# STM32F30xxx register map
File version: 1.0
Registers are 32-bit, read-write, reset 0x0 unless marked. A register's access mark holds for its fields unless they carry their own. Offsets are from the block's base; [hi:lo] are bit positions; {n}, {i} and the like mark numbered series; 'fields as' and 'values as' point back to an identical list.

## DMA1 — DMA controller 1
Base 0x40020000
Same registers: DMA2 0x40020400
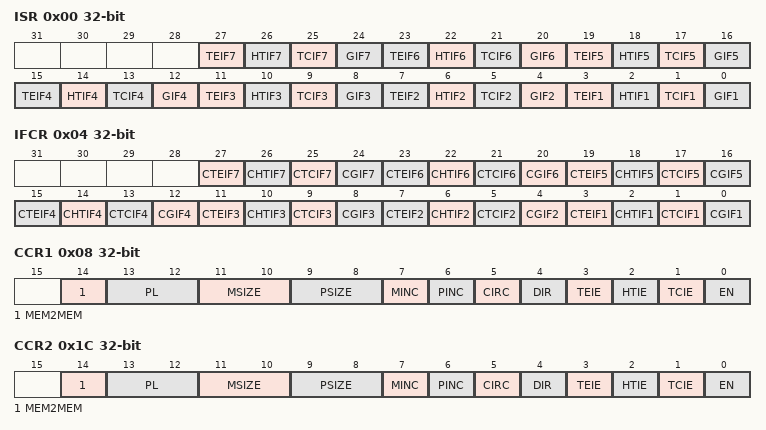
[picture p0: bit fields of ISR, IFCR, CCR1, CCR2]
0x00 ISR ro — DMA interrupt status register (DMA_ISR)
  [4n-1] TEIF{n} (n=1..7) — Channel {n} Transfer Error flag
  [4n-2] HTIF{n} (n=1..7) — Channel {n} Half Transfer Complete flag
  [4n-3] TCIF{n} (n=1..7) — Channel {n} Transfer Complete flag
  [4n-4] GIF{n} (n=1..7) — Channel {n} Global interrupt flag
0x04 IFCR wo — DMA interrupt flag clear register (DMA_IFCR)
  [4n-1] CTEIF{n} (n=1..7) — Channel {n} Transfer Error clear
  [4n-2] CHTIF{n} (n=1..7) — Channel {n} Half Transfer clear
  [4n-3] CTCIF{n} (n=1..7) — Channel {n} Transfer Complete clear
  [4n-4] CGIF{n} (n=1..7) — Channel {n} Global interrupt clear
0x08 CCR1 — DMA channel configuration register (DMA_CCR)
  [14] MEM2MEM — Memory to memory mode
  [13:12] PL — Channel Priority level
  [11:10] MSIZE — Memory size
  [9:8] PSIZE — Peripheral size
  [7] MINC — Memory increment mode
  [6] PINC — Peripheral increment mode
  [5] CIRC — Circular mode
  [4] DIR — Data transfer direction
  [3] TEIE — Transfer error interrupt enable
  [2] HTIE — Half Transfer interrupt enable
  [1] TCIE — Transfer complete interrupt enable
  [0] EN — Channel enable
0x0C CNDTR1 — DMA channel 1 number of data register
  [15:0] NDT — Number of data to transfer
0x10 CPAR1 — DMA channel 1 peripheral address register
  [31:0] PA — Peripheral address
{0x0+0x14*i} CMAR{i} (i=1..7) — DMA channel {i} memory address register
  [31:0] MA — Memory address
0x1C CCR2 — DMA channel configuration register (DMA_CCR)
  fields as CCR1
0x20 CNDTR2 — DMA channel 2 number of data register
  [15:0] NDT — Number of data to transfer
0x24 CPAR2 — DMA channel 2 peripheral address register
  [31:0] PA — Peripheral address
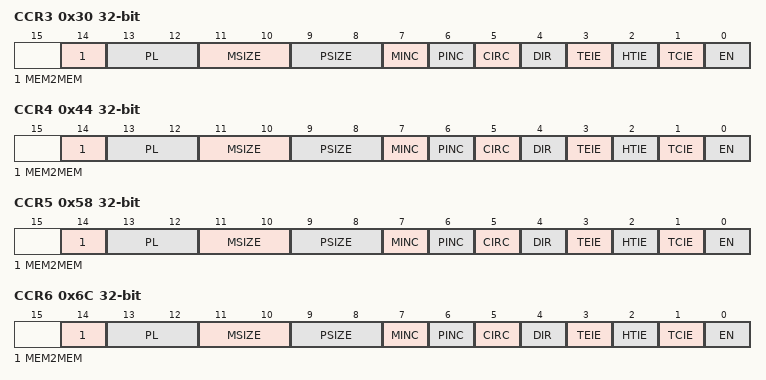
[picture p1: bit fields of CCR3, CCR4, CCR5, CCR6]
0x30 CCR3 — DMA channel configuration register (DMA_CCR)
  fields as CCR1
0x34 CNDTR3 — DMA channel 3 number of data register
  [15:0] NDT — Number of data to transfer
0x38 CPAR3 — DMA channel 3 peripheral address register
  [31:0] PA — Peripheral address
0x44 CCR4 — DMA channel configuration register (DMA_CCR)
  fields as CCR1
0x48 CNDTR4 — DMA channel 4 number of data register
  [15:0] NDT — Number of data to transfer
0x4C CPAR4 — DMA channel 4 peripheral address register
  [31:0] PA — Peripheral address
0x58 CCR5 — DMA channel configuration register (DMA_CCR)
  fields as CCR1
0x5C CNDTR5 — DMA channel 5 number of data register
  [15:0] NDT — Number of data to transfer
0x60 CPAR5 — DMA channel 5 peripheral address register
  [31:0] PA — Peripheral address
0x6C CCR6 — DMA channel configuration register (DMA_CCR)
  fields as CCR1
0x70 CNDTR6 — DMA channel 6 number of data register
  [15:0] NDT — Number of data to transfer
0x74 CPAR6 — DMA channel 6 peripheral address register
  [31:0] PA — Peripheral address
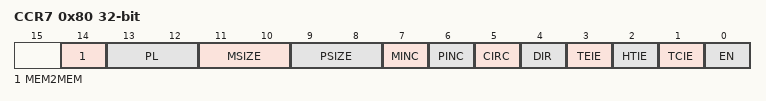
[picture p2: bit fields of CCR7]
0x80 CCR7 — DMA channel configuration register (DMA_CCR)
  fields as CCR1
0x84 CNDTR7 — DMA channel 7 number of data register
  [15:0] NDT — Number of data to transfer
0x88 CPAR7 — DMA channel 7 peripheral address register
  [31:0] PA — Peripheral address

## TIM16 — General-purpose-timers
Base 0x40014400
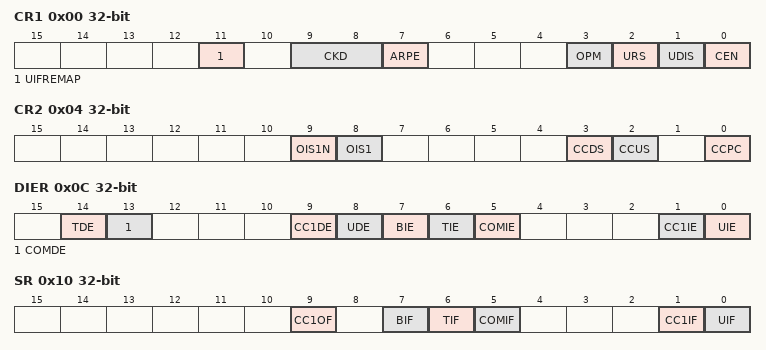
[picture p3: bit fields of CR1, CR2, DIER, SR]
0x00 CR1 — control register 1
  [11] UIFREMAP — UIF status bit remapping
  [9:8] CKD — Clock division
  [7] ARPE — Auto-reload preload enable
  [3] OPM — One-pulse mode
  [2] URS — Update request source
  [1] UDIS — Update disable
  [0] CEN — Counter enable
0x04 CR2 — control register 2
  [9] OIS1N — Output Idle state 1
  [8] OIS1 — Output Idle state 1
  [3] CCDS — Capture/compare DMA selection
  [2] CCUS — Capture/compare control update selection
  [0] CCPC — Capture/compare preloaded control
0x0C DIER — DMA/Interrupt enable register
  [14] TDE — Trigger DMA request enable
  [13] COMDE — COM DMA request enable
  [9] CC1DE — Capture/Compare 1 DMA request enable
  [8] UDE — Update DMA request enable
  [7] BIE — Break interrupt enable
  [6] TIE — Trigger interrupt enable
  [5] COMIE — COM interrupt enable
  [1] CC1IE — Capture/Compare 1 interrupt enable
  [0] UIE — Update interrupt enable
0x10 SR — status register
  [9] CC1OF — Capture/Compare 1 overcapture flag
  [7] BIF — Break interrupt flag
  [6] TIF — Trigger interrupt flag
  [5] COMIF — COM interrupt flag
  [1] CC1IF — Capture/compare 1 interrupt flag
  [0] UIF — Update interrupt flag
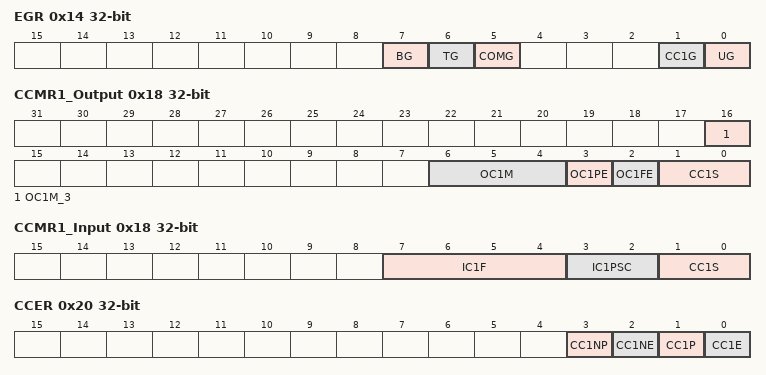
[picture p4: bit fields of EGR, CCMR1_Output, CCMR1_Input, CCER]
0x14 EGR wo — event generation register
  [7] BG — Break generation
  [6] TG — Trigger generation
  [5] COMG — Capture/Compare control update generation
  [1] CC1G — Capture/compare 1 generation
  [0] UG — Update generation
0x18 CCMR1_Output — capture/compare mode register (output mode)
  [16] OC1M_3 — Output Compare 1 mode
  [6:4] OC1M — Output Compare 1 mode
  [3] OC1PE — Output Compare 1 preload enable
  [2] OC1FE — Output Compare 1 fast enable
  [1:0] CC1S — Capture/Compare 1 selection
0x18 CCMR1_Input (alternate view of CCMR1_Output) — capture/compare mode register 1 (input mode)
  [7:4] IC1F — Input capture 1 filter
  [3:2] IC1PSC — Input capture 1 prescaler
  [1:0] CC1S — Capture/Compare 1 selection
0x20 CCER — capture/compare enable register
  [3] CC1NP — Capture/Compare 1 output Polarity
  [2] CC1NE — Capture/Compare 1 complementary output enable
  [1] CC1P — Capture/Compare 1 output Polarity
  [0] CC1E — Capture/Compare 1 output enable
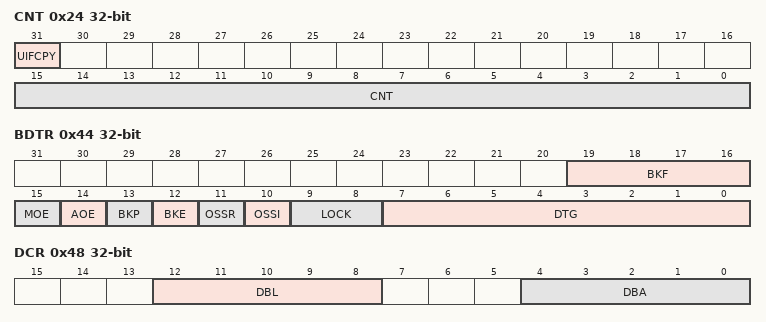
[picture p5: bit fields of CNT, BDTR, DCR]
0x24 CNT access per field — counter
  [31] UIFCPY ro — UIF Copy
  [15:0] CNT rw — counter value
0x28 PSC — prescaler
  [15:0] PSC — Prescaler value
0x2C ARR — auto-reload register
  [15:0] ARR — Auto-reload value
0x30 RCR — repetition counter register
  [7:0] REP — Repetition counter value
0x34 CCR1 — capture/compare register 1
  [15:0] CCR1 — Capture/Compare 1 value
0x44 BDTR — break and dead-time register
  [19:16] BKF — Break filter
  [15] MOE — Main output enable
  [14] AOE — Automatic output enable
  [13] BKP — Break polarity
  [12] BKE — Break enable
  [11] OSSR — Off-state selection for Run mode
  [10] OSSI — Off-state selection for Idle mode
  [9:8] LOCK — Lock configuration
  [7:0] DTG — Dead-time generator setup
0x48 DCR — DMA control register
  [12:8] DBL — DMA burst length
  [4:0] DBA — DMA base address
0x4C DMAR — DMA address for full transfer
  [15:0] DMAB — DMA register for burst accesses
0x50 OR — option register

## TIM17 — General purpose timer
Base 0x40014800
Registers as TIM16, without OR.
